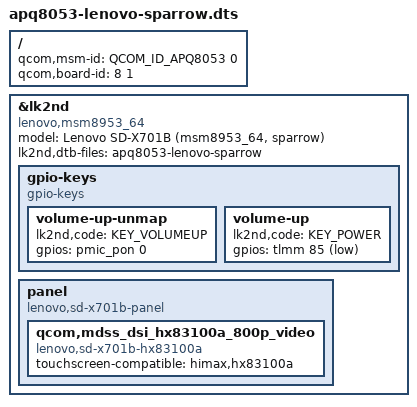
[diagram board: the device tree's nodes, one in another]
// SPDX-License-Identifier: BSD-3-Clause

/dts-v1/;

#include <skeleton64.dtsi>
#include <lk2nd.dtsi>

/ {
	qcom,msm-id = <QCOM_ID_APQ8053 0>;
	qcom,board-id= <8 1>;
};

&lk2nd {
	model = "Lenovo SD-X701B (msm8953_64, sparrow)";
	compatible = "lenovo,msm8953_64";

	lk2nd,dtb-files = "apq8053-lenovo-sparrow";

	gpio-keys {
		compatible = "gpio-keys";

		/* HACK: map KEY_VOLUMEUP to non-existent button so the actual
		 * Volume Up button will successfully re-map to KEY_POWER below.
		 */
		volume-up-unmap {
			lk2nd,code = <KEY_VOLUMEUP>;
			gpios = <&pmic_pon 0 0>;
		};

		/*
		 * Remap Volume Up to KEY_POWER to allow selecting menu items as
		 * there is no power button present on the device.
		 * Use Volume Down to navigate the menu and Volume Up to select.
		 */
		volume-up {
			lk2nd,code = <KEY_POWER>;
			gpios = <&tlmm 85 (GPIO_ACTIVE_LOW | GPIO_PULL_UP)>;
		};
	};

	panel {
		compatible = "lenovo,sd-x701b-panel", "lk2nd,panel";

		qcom,mdss_dsi_hx83100a_800p_video {
			compatible = "lenovo,sd-x701b-hx83100a";
			touchscreen-compatible = "himax,hx83100a";
		};
	};
};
